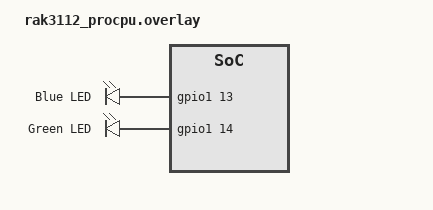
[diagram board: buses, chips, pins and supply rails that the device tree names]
/ {
	aliases {
		blue-led = &blue_led;
		green-led = &green_led;
	};

	leds {
		compatible = "gpio-leds";
		blue_led: led_0 {
			gpios = <&gpio1 13 GPIO_ACTIVE_HIGH>; /* G45 */
			label = "Blue LED";
		};
		green_led: led_1 {
			gpios = <&gpio1 14 GPIO_ACTIVE_HIGH>; /* G46 */
			label = "Green LED";
		};
	};
};
